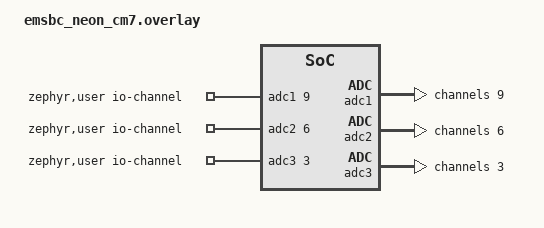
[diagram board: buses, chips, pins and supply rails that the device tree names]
/*
 * Copyright (c) 2025 emtrion GmbH
 *
 * SPDX-License-Identifier: Apache-2.0
 */

/ {
	zephyr,user {
		/* adjust channel number according to pinmux in board.dts */
		io-channels = <&adc1 9>, <&adc2 6>, <&adc3 3>;
	};
};

&adc1 {
	#address-cells = <1>;
	#size-cells = <0>;

	channel@9 {
		reg = <9>;
		zephyr,gain = "ADC_GAIN_1";
		zephyr,reference = "ADC_REF_INTERNAL";
		zephyr,acquisition-time = <ADC_ACQ_TIME_DEFAULT>;
		zephyr,resolution = <12>;
	};
};

&adc2 {
	#address-cells = <1>;
	#size-cells = <0>;

	channel@6 {
		reg = <6>;
		zephyr,gain = "ADC_GAIN_1";
		zephyr,reference = "ADC_REF_INTERNAL";
		zephyr,acquisition-time = <ADC_ACQ_TIME_DEFAULT>;
		zephyr,resolution = <12>;
	};
};

&adc3 {
	#address-cells = <1>;
	#size-cells = <0>;

	channel@3 {
		reg = <3>;
		zephyr,gain = "ADC_GAIN_1";
		zephyr,reference = "ADC_REF_INTERNAL";
		zephyr,acquisition-time = <ADC_ACQ_TIME_DEFAULT>;
		zephyr,resolution = <12>;
	};
};
